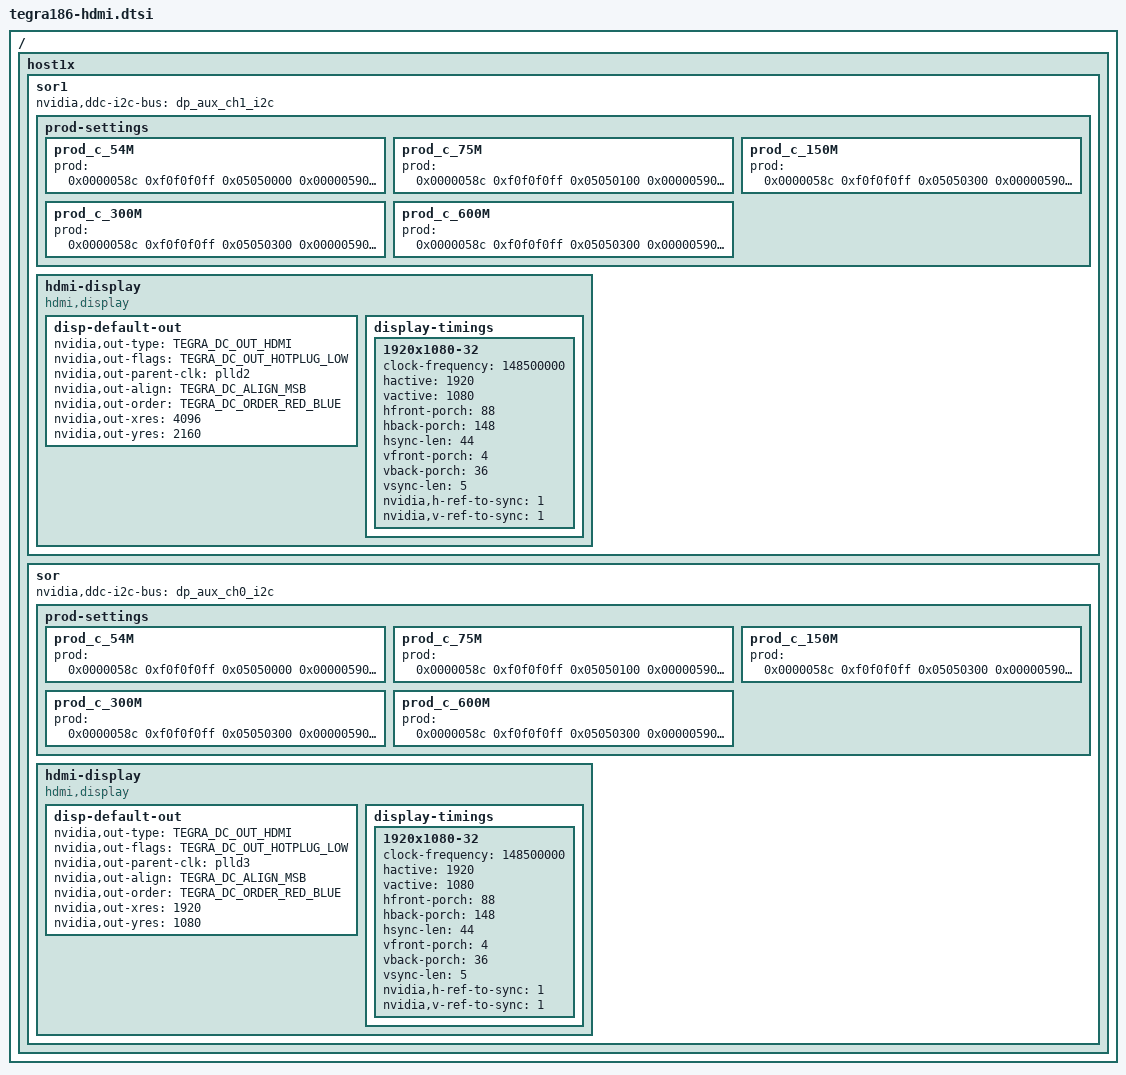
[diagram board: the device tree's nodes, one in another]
/*
 * arch/arm64/boot/dts/tegra186-platforms/tegra186-hdmi.dtsi
 *
 * Copyright (c) 2015-2016, NVIDIA CORPORATION.  All rights reserved.
 *
 * This program is free software; you can redistribute it and/or modify
 * it under the terms of the GNU General Public License as published by
 * the Free Software Foundation; either version 2 of the License, or
 * (at your option) any later version.
 *
 * This program is distributed in the hope that it will be useful, but WITHOUT
 * ANY WARRANTY; without even the implied warranty of MERCHANTABILITY or
 * FITNESS FOR A PARTICULAR PURPOSE.  See the GNU General Public License for
 * more details.
 *
 * You should have received a copy of the GNU General Public License along
 * with this program; if not, write to the Free Software Foundation, Inc.,
 * 51 Franklin Street, Fifth Floor, Boston, MA  02110-1301, USA.
 */

#include <dt-bindings/display/tegra-dc.h>
#include <dt-bindings/gpio/tegra-gpio.h>

/ {
        host1x {
		sor1 {
                        status = "okay";
                        nvidia,ddc-i2c-bus = <&dp_aux_ch1_i2c>;
			prod-settings {
				prod_c_54M {
					prod = <
						0x0000058c 0xf0f0f0ff 0x05050000
						0x00000590 0xff0fe0ff 0x00301300
						0x00000598 0x00fff00f 0x38000440
						0x00000138 0x00000000 0x333A3A3A
						0x00000148 0x00000000 0x00000000
						0x000005a0 0xffbf00ff 0x00401000
						0x000005a8 0x00ffffff 0x52000000
					>;
				};
				prod_c_75M {
					prod = <
						0x0000058c 0xf0f0f0ff 0x05050100
						0x00000590 0xff0fe0ff 0x00301300
						0x00000598 0x00fff00f 0x38000440
						0x00000138 0x00000000 0x333A3A3A
						0x00000148 0x00000000 0x00000000
						0x000005a0 0xffbf00ff 0x00404000
						0x000005a8 0x00ffffff 0x42000000
					>;
				};
				prod_c_150M {
					prod = <
						0x0000058c 0xf0f0f0ff 0x05050300
						0x00000590 0xff0fe0ff 0x00301300
						0x00000598 0x00fff00f 0x38000440
						0x00000138 0x00000000 0x333A3A3A
						0x00000148 0x00000000 0x00000000
						0x000005a0 0xffbf00ff 0x00406600
						0x000005a8 0x00ffffff 0x32000000
					>;
				};
				prod_c_300M {
					prod = <
						0x0000058c 0xf0f0f0ff 0x05050300
						0x00000590 0xff0fe0ff 0x00301300
						0x00000598 0x00fff00f 0x3C000440
						0x00000138 0x00000000 0x333F3F3F
						0x00000148 0x00000000 0x001F1F1F
						0x000005a0 0xffbf00ff 0x00406600
						0x000005a8 0x00ffffff 0x32000000
					>;
				};
				prod_c_600M {
					prod = <
						0x0000058c 0xf0f0f0ff 0x05050300
						0x00000590 0xff0fe0ff 0x00301300
						0x00000598 0x00fff00f 0x3C000440
						0x00000138 0x00000000 0x333C3C3C
						0x00000148 0x00000000 0x001F1F1F
						0x000005a0 0xffbf00ff 0x00406600
						0x000005a8 0x00ffffff 0x32000000
					>;
				};
			};

                        hdmi-display {
                                status = "okay";
                                compatible = "hdmi,display";
                                disp-default-out {
                                        nvidia,out-type = <TEGRA_DC_OUT_HDMI>;
                                        nvidia,out-flags = <TEGRA_DC_OUT_HOTPLUG_LOW>;
					nvidia,out-parent-clk = "plld2";
                                        nvidia,out-align = <TEGRA_DC_ALIGN_MSB>;
                                        nvidia,out-order = <TEGRA_DC_ORDER_RED_BLUE>;
					nvidia,out-xres = <4096>; /* 4096 p*/
					nvidia,out-yres = <2160>; /* 2160 p*/
//					nvidia,out-xres = <1280>; /*720 p*/
//					nvidia,out-yres = <720>;  /*720 p*/
//					nvidia,out-xres = <720>;  /*480 p*/
//					nvidia,out-yres = <480>;  /*480 p */
				};
				/* Setting the default value for testing */
				display-timings {
/*					720x480-32 {
						clock-frequency = <27000000>;
						hactive = <720>;
						vactive = <480>;
						hfront-porch = <16>;
						hback-porch = <60>;
						hsync-len = <62>;
						vfront-porch = <9>;
						vback-porch = <30>;
						vsync-len = <6>;
						nvidia,h-ref-to-sync = <1>;
						nvidia,v-ref-to-sync = <1>;
					};

*/
/*					1280x720-32 {
						clock-frequency = <74250000>;
						hactive = <1280>;
						vactive = <720>;
						hfront-porch = <110>;
						hback-porch = <220>;
						hsync-len = <40>;
						vfront-porch = <5>;
						vback-porch = <20>;
						vsync-len = <5>;
						nvidia,h-ref-to-sync = <1>;
						nvidia,v-ref-to-sync = <1>;
					};
*/
					1920x1080-32 {
						clock-frequency = <148500000>;
						hactive = <1920>;
						vactive = <1080>;
						hfront-porch = <88>;
						hback-porch = <148>;
						hsync-len = <44>;
						vfront-porch = <4>;
						vback-porch = <36>;
						vsync-len = <5>;
						nvidia,h-ref-to-sync = <1>;
						nvidia,v-ref-to-sync = <1>;
					};
				};
			};
		};

		sor {
			status = "okay";
			nvidia,ddc-i2c-bus = <&dp_aux_ch0_i2c>;
			prod-settings {
				prod_c_54M {
					prod = <
						0x0000058c 0xf0f0f0ff 0x05050000
						0x00000590 0xff0fe0ff 0x00301300
						0x00000598 0x00fff00f 0x38000440
						0x00000138 0x00000000 0x333A3A3A
						0x00000148 0x00000000 0x00000000
						0x000005a0 0xffbf00ff 0x00401000
						0x000005a8 0x00ffffff 0x52000000
					>;
				};
				prod_c_75M {
					prod = <
						0x0000058c 0xf0f0f0ff 0x05050100
						0x00000590 0xff0fe0ff 0x00301300
						0x00000598 0x00fff00f 0x38000440
						0x00000138 0x00000000 0x333A3A3A
						0x00000148 0x00000000 0x00000000
						0x000005a0 0xffbf00ff 0x00404000
						0x000005a8 0x00ffffff 0x42000000
					>;
				};
				prod_c_150M {
					prod = <
						0x0000058c 0xf0f0f0ff 0x05050300
						0x00000590 0xff0fe0ff 0x00301300
						0x00000598 0x00fff00f 0x38000440
						0x00000138 0x00000000 0x333A3A3A
						0x00000148 0x00000000 0x00000000
						0x000005a0 0xffbf00ff 0x00406600
						0x000005a8 0x00ffffff 0x32000000
					>;
				};
				prod_c_300M {
					prod = <
						0x0000058c 0xf0f0f0ff 0x05050300
						0x00000590 0xff0fe0ff 0x00301300
						0x00000598 0x00fff00f 0x3C000440
						0x00000138 0x00000000 0x333C3C3C
						0x00000148 0x00000000 0x001F1F1F
						0x000005a0 0xffbf00ff 0x00406600
						0x000005a8 0x00ffffff 0x32000000
					>;
				};
				prod_c_600M {
					prod = <
						0x0000058c 0xf0f0f0ff 0x05050300
						0x00000590 0xff0fe0ff 0x00301300
						0x00000598 0x00fff00f 0x3C000440
						0x00000138 0x00000000 0x333F3F3F
						0x00000148 0x00000000 0x001F1F1F
						0x000005a0 0xffbf00ff 0x00406600
						0x000005a8 0x00ffffff 0x32000000
					>;
				};
			};

			hdmi-display {
				status = "okay";
				compatible = "hdmi,display";
				disp-default-out {
					nvidia,out-type = <TEGRA_DC_OUT_HDMI>;
					nvidia,out-flags = <TEGRA_DC_OUT_HOTPLUG_LOW>;
					nvidia,out-parent-clk = "plld3";
					nvidia,out-align = <TEGRA_DC_ALIGN_MSB>;
					nvidia,out-order = <TEGRA_DC_ORDER_RED_BLUE>;
					nvidia,out-xres = <1920>; /* 1080 p*/
					nvidia,out-yres = <1080>; /* 1080 p*/
//					nvidia,out-xres = <1280>; /*720 p*/
//					nvidia,out-yres = <720>;  /*720 p*/
//					nvidia,out-xres = <720>;  /*480 p*/
//					nvidia,out-yres = <480>;  /*480 p */
				};
				/* Setting the default value for testing */
				display-timings {
/*					720x480-32 {
						clock-frequency = <27000000>;
						hactive = <720>;
						vactive = <480>;
						hfront-porch = <16>;
						hback-porch = <60>;
						hsync-len = <62>;
						vfront-porch = <9>;
						vback-porch = <30>;
						vsync-len = <6>;
						nvidia,h-ref-to-sync = <1>;
						nvidia,v-ref-to-sync = <1>;
					};

*/
/*					1280x720-32 {
						clock-frequency = <74250000>;
						hactive = <1280>;
						vactive = <720>;
						hfront-porch = <110>;
						hback-porch = <220>;
						hsync-len = <40>;
						vfront-porch = <5>;
						vback-porch = <20>;
						vsync-len = <5>;
						nvidia,h-ref-to-sync = <1>;
						nvidia,v-ref-to-sync = <1>;
					};
*/
					1920x1080-32 {
						clock-frequency = <148500000>;
						hactive = <1920>;
						vactive = <1080>;
						hfront-porch = <88>;
						hback-porch = <148>;
						hsync-len = <44>;
						vfront-porch = <4>;
						vback-porch = <36>;
						vsync-len = <5>;
						nvidia,h-ref-to-sync = <1>;
						nvidia,v-ref-to-sync = <1>;
					};


				};
			};
		};
	};
};

